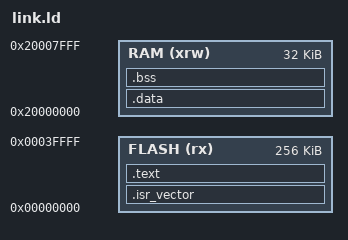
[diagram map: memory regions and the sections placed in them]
/* Specify the memory areas */
MEMORY
{
  FLASH (rx)      : ORIGIN = 0x00000000, LENGTH = 256K
  RAM (xrw)       : ORIGIN = 0x20000000, LENGTH = 32K
}

SECTIONS {
    /* Vectors first - Always permitted by MPU */
    .isr_vector :
    {
        . = ALIGN(4);
        KEEP(*(.isr_vector))
        . = ALIGN(4);
    } > FLASH

    .text :
    {
        . = ALIGN(8);
        _stext = .;
        *(.text*)
        *(.rodata*)
        . = ALIGN(8);

        _etext = .;
    } > FLASH

    _sidata = .;
    .data : AT ( _sidata )
    {
        . = ALIGN(4);
        _sdata = .;         /* create a global symbol at data start */
        *(.data*)           /* .data sections */
        . = ALIGN(4);
        _edata = .;         /* define a global symbol at data end */
    } > RAM

    /* Uninitialized data section */
    _sibss = .;
    .bss : AT ( _sibss )
    {
        . = ALIGN(4);
        _sbss = .;         /* define a global symbol at bss start */
        *(.bss*)
        *(COMMON)

        . = ALIGN(4);
        _ebss = .;         /* define a global symbol at bss end */
    } > RAM
}

PROVIDE(end = .);
_end            = .;
